# PIC32MX170F512H register map
Vendor: Microchip
Registers are 32-bit, read-write, reset 0x0 unless marked. A register's access mark holds for its fields unless they carry their own. Addresses are absolute, and some are shared; only a register's first bit layout is shown; [hi:lo] are bit positions; {n}, {i} and the like mark numbered series.

## PORTB
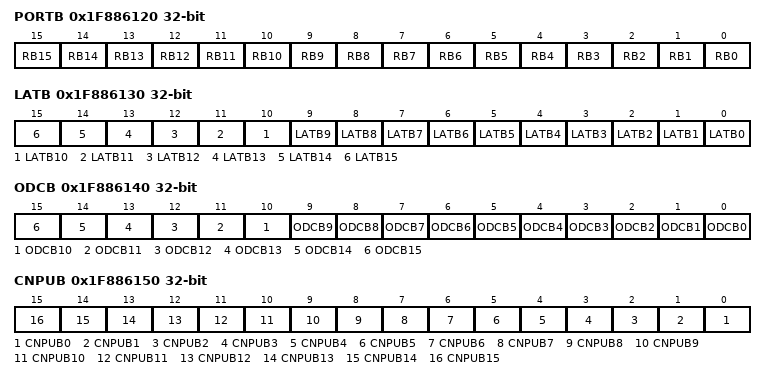
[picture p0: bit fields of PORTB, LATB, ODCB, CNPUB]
0x1F886120 PORTB reset not defined — (power-on value ----------------xxxxxxxxxxxxxxxx)
  [n] RB{n} (n=0..15)
0x1F886130 LATB reset not defined — (power-on value ----------------xxxxxxxxxxxxxxxx)
  [n] LATB{n} (n=0..15)
0x1F886140 ODCB
  [n] ODCB{n} (n=0..15)
0x1F886150 CNPUB reset not defined — (power-on value ----------------xxxxxxxxxxxxxxxx)
  [n] CNPUB{n} (n=0..15)
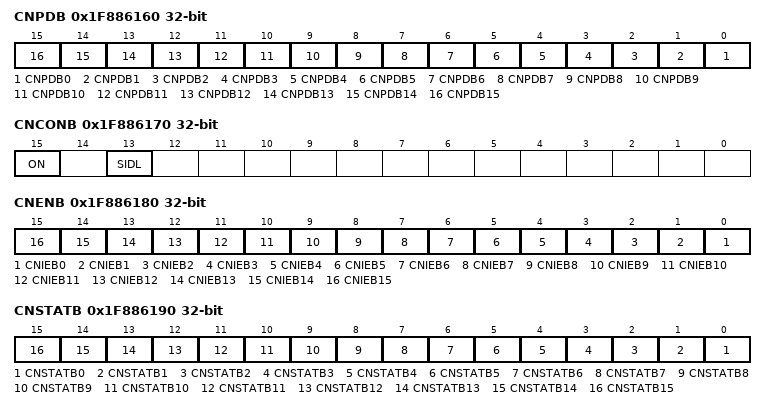
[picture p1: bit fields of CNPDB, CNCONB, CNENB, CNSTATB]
0x1F886160 CNPDB reset not defined — (power-on value ----------------xxxxxxxxxxxxxxxx)
  [n] CNPDB{n} (n=0..15)
0x1F886170 CNCONB
  [15] ON, [13] SIDL
0x1F886180 CNENB reset not defined — (power-on value 0000000000------xxxxxxxxxxxxxxxx)
  [n] CNIEB{n} (n=0..15)
0x1F886190 CNSTATB reset not defined — (power-on value ----------------xxxxxxxxxxxxxxxx)
  [n] CNSTATB{n} (n=0..15)

## PORTC
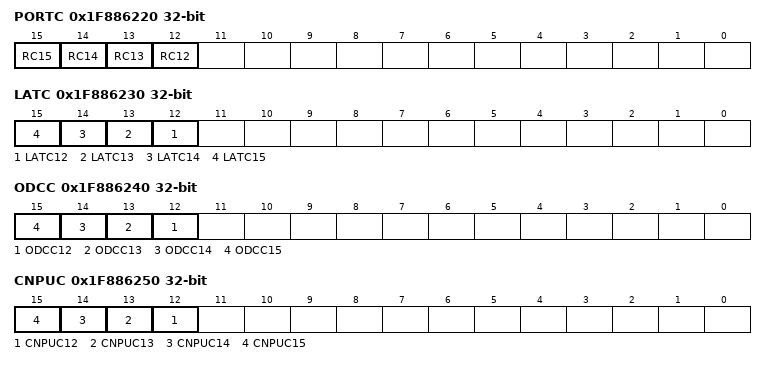
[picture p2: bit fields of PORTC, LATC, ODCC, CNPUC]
0x1F886220 PORTC reset not defined — (power-on value ----------------xxxx------------)
  [n] RC{n} (n=12..15)
0x1F886230 LATC reset not defined — (power-on value ----------------xxxx------------)
  [n] LATC{n} (n=12..15)
0x1F886240 ODCC
  [n] ODCC{n} (n=12..15)
0x1F886250 CNPUC reset not defined — (power-on value ----------------xxxx------------)
  [n] CNPUC{n} (n=12..15)
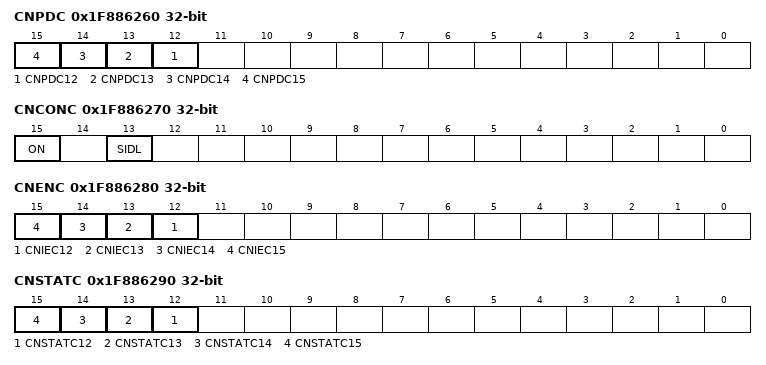
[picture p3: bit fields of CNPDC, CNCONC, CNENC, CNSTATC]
0x1F886260 CNPDC reset not defined — (power-on value ----------------xxxx------------)
  [n] CNPDC{n} (n=12..15)
0x1F886270 CNCONC
  [15] ON, [13] SIDL
0x1F886280 CNENC reset not defined — (power-on value 0000000000------xxxx------------)
  [n] CNIEC{n} (n=12..15)
0x1F886290 CNSTATC reset not defined — (power-on value ----------------xxxx------------)
  [n] CNSTATC{n} (n=12..15)

## PORTD
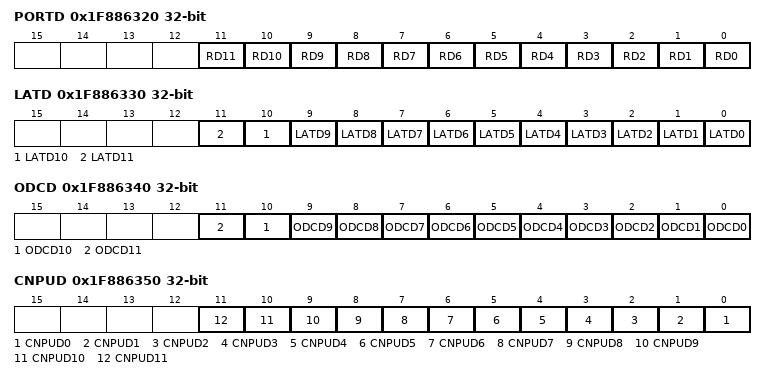
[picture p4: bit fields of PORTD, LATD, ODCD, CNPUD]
0x1F886320 PORTD reset not defined — (power-on value --------------------xxxxxxxxxxxx)
  [n] RD{n} (n=0..11)
0x1F886330 LATD reset not defined — (power-on value --------------------xxxxxxxxxxxx)
  [n] LATD{n} (n=0..11)
0x1F886340 ODCD
  [n] ODCD{n} (n=0..11)
0x1F886350 CNPUD reset not defined — (power-on value --------------------xxxxxxxxxxxx)
  [n] CNPUD{n} (n=0..11)
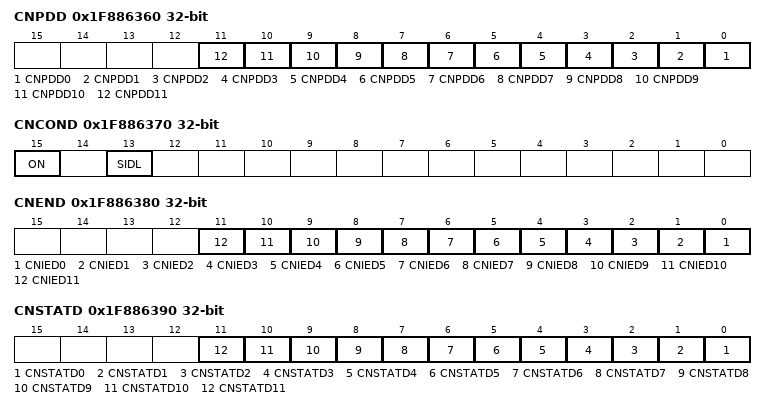
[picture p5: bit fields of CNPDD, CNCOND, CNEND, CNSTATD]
0x1F886360 CNPDD reset not defined — (power-on value --------------------xxxxxxxxxxxx)
  [n] CNPDD{n} (n=0..11)
0x1F886370 CNCOND
  [15] ON, [13] SIDL
0x1F886380 CNEND reset not defined — (power-on value 0000000000----------xxxxxxxxxxxx)
  [n] CNIED{n} (n=0..11)
0x1F886390 CNSTATD reset not defined — (power-on value --------------------xxxxxxxxxxxx)
  [n] CNSTATD{n} (n=0..11)

## PORTE
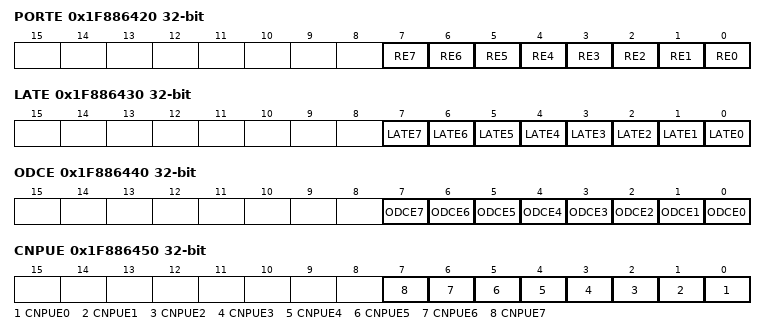
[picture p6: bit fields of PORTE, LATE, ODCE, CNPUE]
0x1F886420 PORTE reset not defined — (power-on value ------------------------xxxxxxxx)
  [n] RE{n} (n=0..7)
0x1F886430 LATE reset not defined — (power-on value ------------------------xxxxxxxx)
  [n] LATE{n} (n=0..7)
0x1F886440 ODCE
  [n] ODCE{n} (n=0..7)
0x1F886450 CNPUE reset not defined — (power-on value ------------------------xxxxxxxx)
  [n] CNPUE{n} (n=0..7)
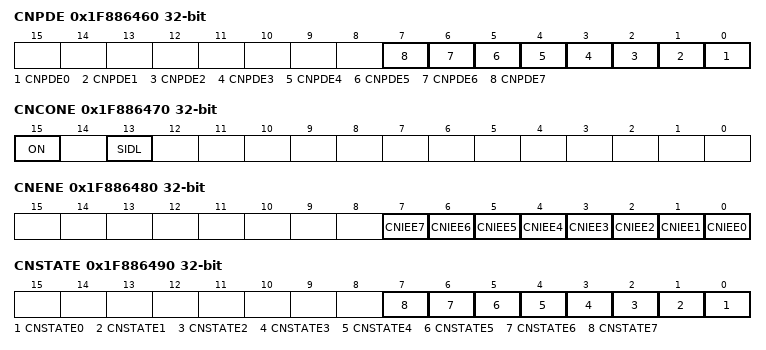
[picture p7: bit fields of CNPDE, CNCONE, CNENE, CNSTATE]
0x1F886460 CNPDE reset not defined — (power-on value ------------------------xxxxxxxx)
  [n] CNPDE{n} (n=0..7)
0x1F886470 CNCONE
  [15] ON, [13] SIDL
0x1F886480 CNENE reset not defined — (power-on value 0000000000--------------xxxxxxxx)
  [n] CNIEE{n} (n=0..7)
0x1F886490 CNSTATE reset not defined — (power-on value ------------------------xxxxxxxx)
  [n] CNSTATE{n} (n=0..7)

## PORTF
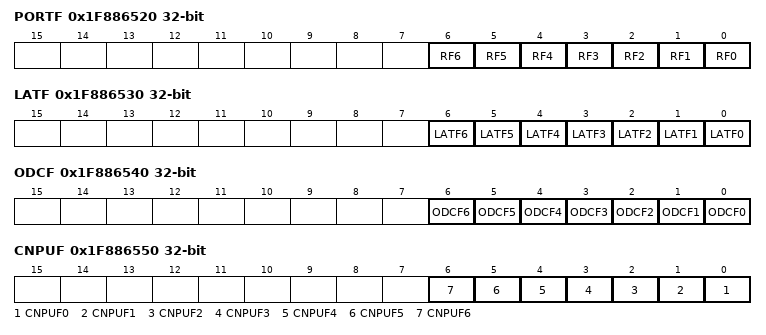
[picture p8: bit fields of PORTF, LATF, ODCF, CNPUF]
0x1F886520 PORTF reset not defined — (power-on value -------------------------xxxxxxx)
  [n] RF{n} (n=0..6)
0x1F886530 LATF reset not defined — (power-on value -------------------------xxxxxxx)
  [n] LATF{n} (n=0..6)
0x1F886540 ODCF
  [n] ODCF{n} (n=0..6)
0x1F886550 CNPUF reset not defined — (power-on value -------------------------xxxxxxx)
  [n] CNPUF{n} (n=0..6)
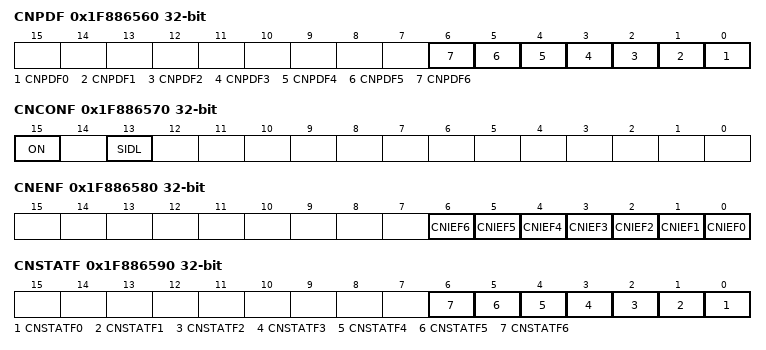
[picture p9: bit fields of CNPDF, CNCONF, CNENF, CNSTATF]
0x1F886560 CNPDF reset not defined — (power-on value -------------------------xxxxxxx)
  [n] CNPDF{n} (n=0..6)
0x1F886570 CNCONF
  [15] ON, [13] SIDL
0x1F886580 CNENF reset not defined — (power-on value 0000000000---------------xxxxxxx)
  [n] CNIEF{n} (n=0..6)
0x1F886590 CNSTATF reset not defined — (power-on value -------------------------xxxxxxx)
  [n] CNSTATF{n} (n=0..6)

## PORTG
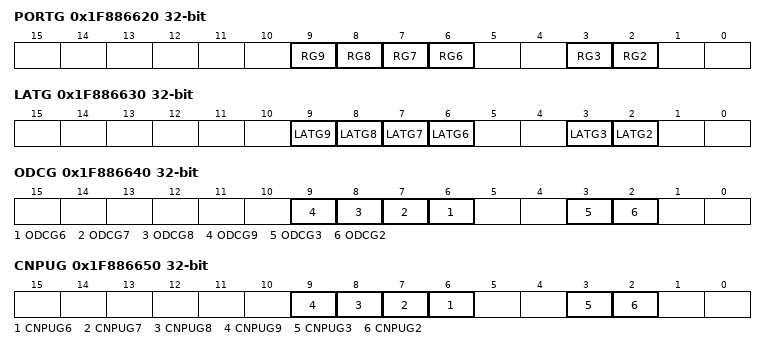
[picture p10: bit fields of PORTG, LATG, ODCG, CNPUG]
0x1F886620 PORTG reset not defined — (power-on value ----------------------xxxx--xx--)
  [n] RG{n} (n=6..9), [3] RG3, [2] RG2
0x1F886630 LATG reset not defined — (power-on value ----------------------xxxx--xx--)
  [n] LATG{n} (n=6..9), [3] LATG3, [2] LATG2
0x1F886640 ODCG
  [n] ODCG{n} (n=6..9), [3] ODCG3, [2] ODCG2
0x1F886650 CNPUG reset not defined — (power-on value ----------------------xxxx--xx--)
  [n] CNPUG{n} (n=6..9), [3] CNPUG3, [2] CNPUG2
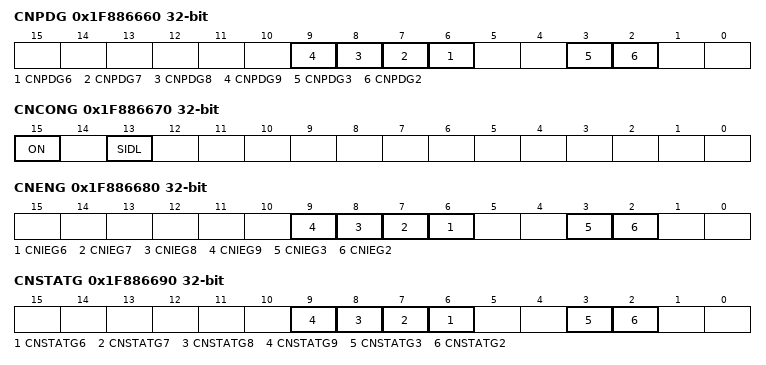
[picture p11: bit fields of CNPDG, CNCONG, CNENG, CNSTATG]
0x1F886660 CNPDG reset not defined — (power-on value ----------------------xxxx--xx--)
  [n] CNPDG{n} (n=6..9), [3] CNPDG3, [2] CNPDG2
0x1F886670 CNCONG
  [15] ON, [13] SIDL
0x1F886680 CNENG reset not defined — (power-on value 0000000000------------xxxx--xx--)
  [n] CNIEG{n} (n=6..9), [3] CNIEG3, [2] CNIEG2
0x1F886690 CNSTATG reset not defined — (power-on value ----------------------xxxx--xx--)
  [n] CNSTATG{n} (n=6..9), [3] CNSTATG3, [2] CNSTATG2
